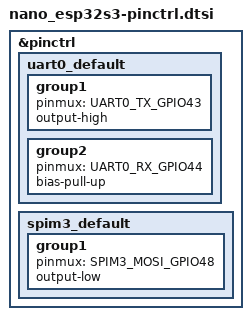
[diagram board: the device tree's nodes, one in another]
/*
 * Copyright (c) 2026 MuseLab nanoESP32-S3 Zephyr port
 * SPDX-License-Identifier: Apache-2.0
 */

#include <zephyr/dt-bindings/pinctrl/esp-pinctrl-common.h>
#include <zephyr/dt-bindings/pinctrl/esp32s3-pinctrl.h>
#include <zephyr/dt-bindings/pinctrl/esp32s3-gpio-sigmap.h>

&pinctrl {
	/* UART0 wired to on-board ESPLink USB-to-serial bridge */
	uart0_default: uart0_default {
		group1 {
			pinmux = <UART0_TX_GPIO43>;
			output-high;
		};

		group2 {
			pinmux = <UART0_RX_GPIO44>;
			bias-pull-up;
		};
	};

	/* WS2812B RGB LED data-in on GPIO48, driven as SPI3 MOSI */
	spim3_default: spim3_default {
		group1 {
			pinmux = <SPIM3_MOSI_GPIO48>;
			output-low;
		};
	};
};
